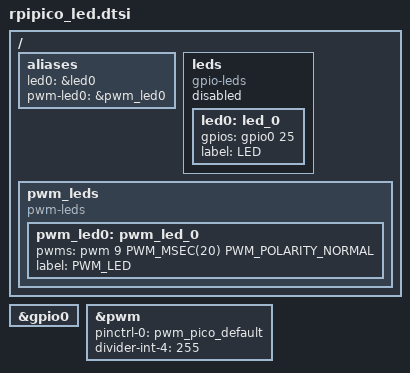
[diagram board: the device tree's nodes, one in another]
/*
 * Copyright (c) 2023 TiaC Systems
 * SPDX-License-Identifier: Apache-2.0
 */

#include <zephyr/dt-bindings/gpio/gpio.h>
#include <zephyr/dt-bindings/pwm/pwm.h>

/ {
	aliases {
		led0 = &led0;
		pwm-led0 = &pwm_led0;
	};

	leds {
		compatible = "gpio-leds";
		status = "disabled";

		led0: led_0 {
			gpios = <&gpio0 25 GPIO_ACTIVE_HIGH>;
			label = "LED";
		};
	};

	pwm_leds {
		compatible = "pwm-leds";
		status = "okay";

		pwm_led0: pwm_led_0 {
			pwms = <&pwm 9 PWM_MSEC(20) PWM_POLARITY_NORMAL>;
			label = "PWM_LED";
		};
	};
};

&gpio0 {
	status = "okay";
};

&pwm {
	status = "okay";
	pinctrl-0 = <&pwm_pico_default>;
	pinctrl-names = "default";
	divider-int-4 = <255>;
};
